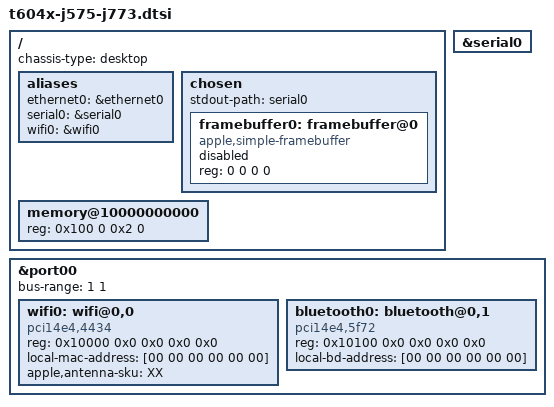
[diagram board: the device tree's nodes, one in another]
// SPDX-License-Identifier: GPL-2.0+ OR MIT
/*
 * This file contains the parts common to the M4 Pro Mac mini (J773s)
 * and M4 Max Mac Studio (J575c).
 *
 * target-type: J575c / J773s
 *
 * Copyright The Asahi Linux Contributors
 */

/ {
	chassis-type = "desktop";

	aliases {
		ethernet0 = &ethernet0;
		serial0 = &serial0;
		wifi0 = &wifi0;
	};

	chosen {
		ranges;
		#address-cells = <2>;
		#size-cells = <2>;

		stdout-path = "serial0";

		framebuffer0: framebuffer@0 {
			compatible = "apple,simple-framebuffer",
			             "simple-framebuffer";
			reg = <0 0 0 0>; /* To be filled by loader */
			/* Format properties will be added by loader */

			status = "disabled";
		};
	};

	memory@10000000000 {
		device_type = "memory";
		reg = <0x100 0 0x2 0>; /* To be filled by loader */
	};
};

&serial0 {
	status = "okay";
};

/*
 * Force the bus number assignments so that we can declare some of the
 * on-board devices and properties that are populated by the bootloader
 * (such as MAC addresses).
 */
&port00 {
	bus-range = <1 1>;

	wifi0: wifi@0,0 {
		compatible = "pci14e4,4434";
		reg = <0x10000 0x0 0x0 0x0 0x0>;
		/* To be filled by the loader */
		local-mac-address = [00 00 00 00 00 00];
		apple,antenna-sku = "XX";
	};

	bluetooth0: bluetooth@0,1 {
		compatible = "pci14e4,5f72";
		reg = <0x10100 0x0 0x0 0x0 0x0>;
		/* To be filled by the loader */
		local-bd-address = [00 00 00 00 00 00];
	};
};

/delete-node/ &ps_isp_cpu;
/delete-node/ &ps_isp_fe;
/delete-node/ &ps_isp_sys;
